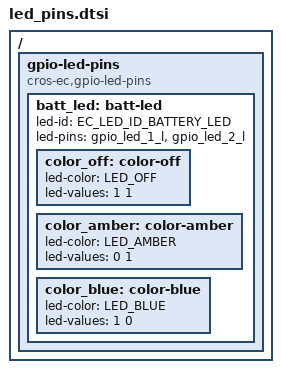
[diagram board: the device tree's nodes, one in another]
/* Copyright 2023 The ChromiumOS Authors
 * Use of this source code is governed by a BSD-style license that can be
 * found in the LICENSE file.
 */

/ {
	gpio-led-pins {
		compatible = "cros-ec,gpio-led-pins";

		batt_led: batt-led {
			led-id = "EC_LED_ID_BATTERY_LED";
			led-pins = <&gpio_led_1_l &gpio_led_2_l>;
			color_off: color-off {
				led-color = "LED_OFF";
				led-values = <1 1>;
			};

			color_amber: color-amber {
				led-color = "LED_AMBER";
				led-values = <0 1>;
			};

			color_blue: color-blue {
				led-color = "LED_BLUE";
				led-values = <1 0>;
			};
		};
	};
};
